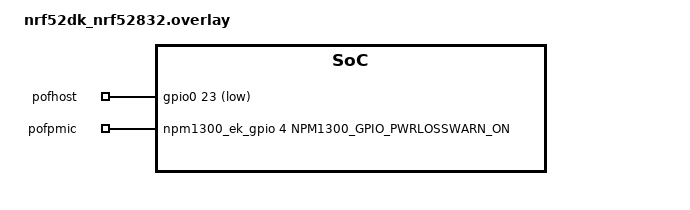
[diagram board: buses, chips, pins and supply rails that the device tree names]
/*
 * Copyright (C) 2023 Nordic Semiconductor ASA
 * SPDX-License-Identifier: Apache-2.0
 */

#include "dt-bindings/gpio/nordic-npm1300-gpio.h"

 &i2c0_default {
	group1 {
		bias-pull-up;
	};
};

&npm1300_ek_regulators {
        dvs-gpios = <&gpio0 17 GPIO_ACTIVE_LOW>,
                    <&gpio0 18 GPIO_ACTIVE_LOW>;
};

&npm1300_ek_buck1 {
        regulator-init-microvolt = <2000000>;
};

/ {
power_loss_warn {
	compatible = "gpio-keys";
	pofhost: pof_host {
		gpios = <&gpio0 23 GPIO_ACTIVE_LOW>;
	};
	pofpmic: pof_pmic {
		gpios = <&npm1300_ek_gpio 4 NPM1300_GPIO_PWRLOSSWARN_ON>;
	};
};
};
